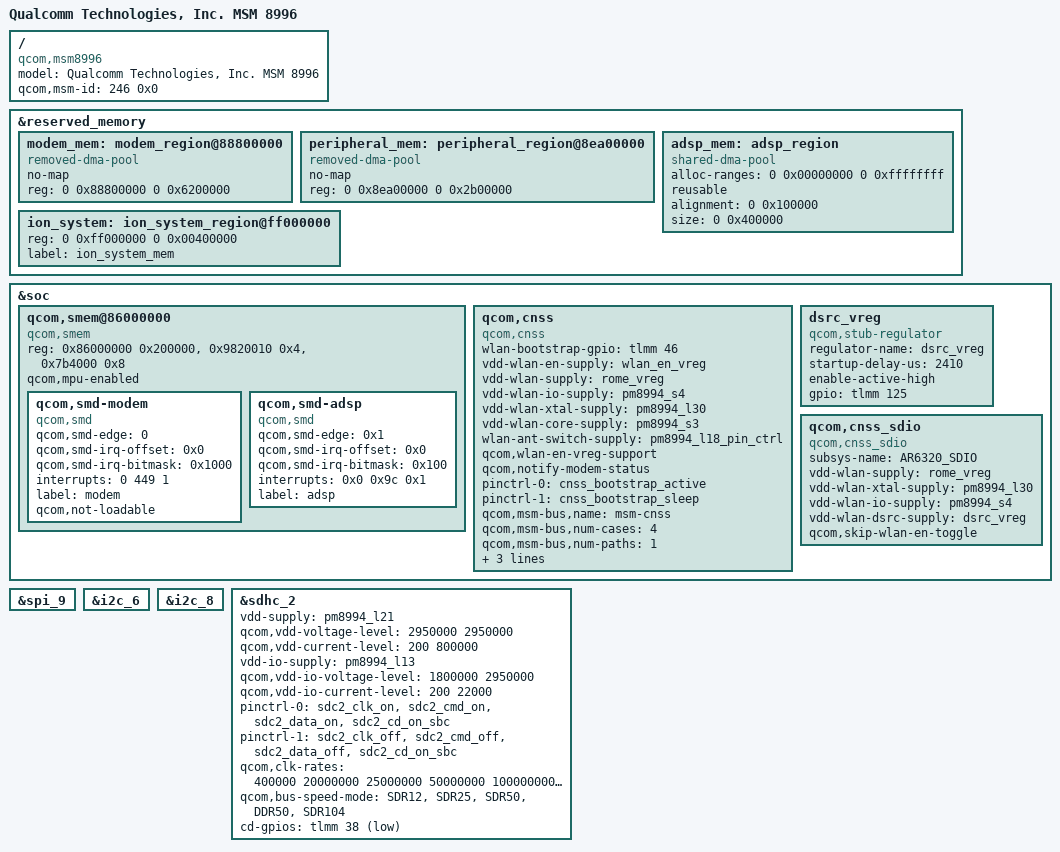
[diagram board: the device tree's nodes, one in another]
/* Copyright (c) 2017-2018, The Linux Foundation. All rights reserved.
 *
 * This program is free software; you can redistribute it and/or modify
 * it under the terms of the GNU General Public License version 2 and
 * only version 2 as published by the Free Software Foundation.
 *
 * This program is distributed in the hope that it will be useful,
 * but WITHOUT ANY WARRANTY; without even the implied warranty of
 * MERCHANTABILITY or FITNESS FOR A PARTICULAR PURPOSE.  See the
 * GNU General Public License for more details.
 */

/dts-v1/;

#include "skeleton64.dtsi"
#include "vplatform-lfv-msm8996.dtsi"
#include "vplatform-lfv-smmu.dtsi"
#include "msm8996-smp2p.dtsi"
#include "vplatform-lfv-msm8996-audio.dtsi"
#include "vplatform-lfv-msm8996-modem.dtsi"
#include <dt-bindings/clock/msm-clocks-8996.h>
#include <dt-bindings/interrupt-controller/arm-gic.h>
#include <dt-bindings/gpio/gpio.h>

/ {
	model = "Qualcomm Technologies, Inc. MSM 8996";
	compatible = "qcom,msm8996";
	qcom,msm-id = <246 0x0>;
};

&reserved_memory {
	modem_mem: modem_region@88800000 {
		compatible = "removed-dma-pool";
		no-map;
		reg = <0 0x88800000 0 0x6200000>;
	};

	peripheral_mem: peripheral_region@8ea00000 {
		compatible = "removed-dma-pool";
		no-map;
		reg = <0 0x8ea00000 0 0x2b00000>;
	};

	adsp_mem: adsp_region {
		compatible = "shared-dma-pool";
		alloc-ranges = <0 0x00000000 0 0xffffffff>;
		reusable;
		alignment = <0 0x100000>;
		size = <0 0x400000>;
	};

	ion_system: ion_system_region@ff000000 {
		reg = <0 0xff000000 0 0x00400000>;
		label = "ion_system_mem";
	};
};

&soc {
	qcom,smem@86000000 {
		compatible = "qcom,smem";
		reg = <0x86000000 0x200000>,
			<0x9820010 0x4>,
			<0x7b4000 0x8>;
		reg-names = "smem", "irq-reg-base",
			"smem_targ_info_reg";
		qcom,mpu-enabled;

		qcom,smd-modem {
			compatible = "qcom,smd";
			qcom,smd-edge = <0>;
			qcom,smd-irq-offset = <0x0>;
			qcom,smd-irq-bitmask = <0x1000>;
			interrupts = <0 449 1>;
			label = "modem";
			qcom,not-loadable;
		};

		qcom,smd-adsp {
			compatible = "qcom,smd";
			qcom,smd-edge = <0x1>;
			qcom,smd-irq-offset = <0x0>;
			qcom,smd-irq-bitmask = <0x100>;
			interrupts = <0x0 0x9c 0x1>;
			label = "adsp";
		};
	};

	qcom,cnss {
		compatible = "qcom,cnss";
		wlan-bootstrap-gpio = <&tlmm 46 0>;
		vdd-wlan-en-supply = <&wlan_en_vreg>;
		vdd-wlan-supply = <&rome_vreg>;
		vdd-wlan-io-supply = <&pm8994_s4>;
		vdd-wlan-xtal-supply = <&pm8994_l30>;
		vdd-wlan-core-supply = <&pm8994_s3>;
		wlan-ant-switch-supply = <&pm8994_l18_pin_ctrl>;
		qcom,wlan-en-vreg-support;
		qcom,notify-modem-status;
		pinctrl-names = "bootstrap_active", "bootstrap_sleep";
		pinctrl-0 = <&cnss_bootstrap_active>;
		pinctrl-1 = <&cnss_bootstrap_sleep>;

		qcom,msm-bus,name = "msm-cnss";
		qcom,msm-bus,num-cases = <4>;
		qcom,msm-bus,num-paths = <1>;
		qcom,msm-bus,vectors-KBps =
					/* No vote */
					<45 512 0 0>,
					/* Up to 200 Mbps */
					<45 512 41421 1520000>,
					/* Up to 400 Mbps */
					<45 512 96650 1520000>,
					/* Up to 800 Mbps */
					<45 512 207108 14432000>;
	};

	dsrc_vreg: dsrc_vreg {
		compatible = "qcom,stub-regulator";
		regulator-name = "dsrc_vreg";
		startup-delay-us = <2410>;
		enable-active-high;
		gpio = <&tlmm 125 0>;
	};

	qcom,cnss_sdio {
		compatible = "qcom,cnss_sdio";
		subsys-name = "AR6320_SDIO";
		vdd-wlan-supply = <&rome_vreg>;
		vdd-wlan-xtal-supply = <&pm8994_l30>;
		vdd-wlan-io-supply = <&pm8994_s4>;
		vdd-wlan-dsrc-supply = <&dsrc_vreg>;
		qcom,skip-wlan-en-toggle;
	};
};

&spi_9 {
	status = "okay";
};

&i2c_6 {
	status = "okay";
};

&i2c_8 {
	status = "okay";
};

&sdhc_2 {
	vdd-supply = <&pm8994_l21>;
	qcom,vdd-voltage-level = <2950000 2950000>;
	qcom,vdd-current-level = <200 800000>;

	vdd-io-supply = <&pm8994_l13>;
	qcom,vdd-io-voltage-level = <1800000 2950000>;
	qcom,vdd-io-current-level = <200 22000>;

	pinctrl-names = "active", "sleep";
	pinctrl-0 = <&sdc2_clk_on &sdc2_cmd_on &sdc2_data_on &sdc2_cd_on_sbc>;
	pinctrl-1 = <&sdc2_clk_off &sdc2_cmd_off &sdc2_data_off
			&sdc2_cd_on_sbc>;

	qcom,clk-rates = <400000 20000000 25000000
				50000000 100000000 200000000>;
	qcom,bus-speed-mode = "SDR12", "SDR25", "SDR50", "DDR50", "SDR104";

	cd-gpios = <&tlmm 38 GPIO_ACTIVE_LOW>;

	status = "okay";
};
